# K210 register map
Vendor: Canaan Inc.; File version: 1.0
Registers are 32-bit, read-write, reset 0x0 unless marked. A register's access mark holds for its fields unless they carry their own. Offsets are from the block's base; [hi:lo] are bit positions; {n}, {i} and the like mark numbered series; 'fields as' and 'values as' point back to an identical list.

## KPU — Neural Network Accelerator
Base 0x40800000
0x00 layer_argument_fifo 64-bit (reset mask 0xFFFFFFFF) — Layer arguments FIFO: each layer is defined by writing 12 successive argument values to this register
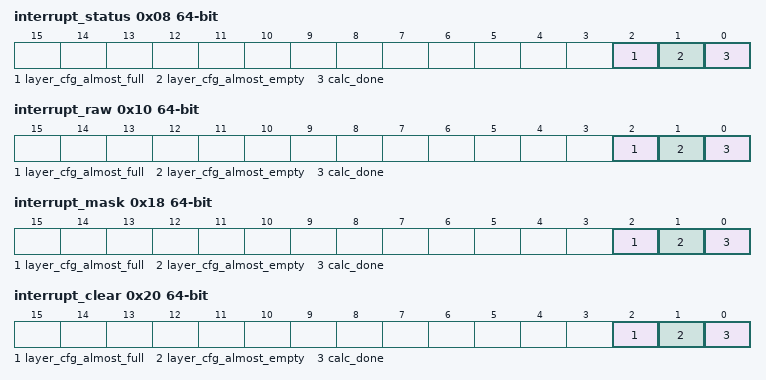
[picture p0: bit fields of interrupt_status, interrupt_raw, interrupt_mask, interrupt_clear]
0x08 interrupt_status 64-bit
  [2] layer_cfg_almost_full — Interrupt raised when layer arguments FIFO almost full
  [1] layer_cfg_almost_empty — Interrupt raised when layer arguments FIFO almost empty
  [0] calc_done — Interrupt raised when calculation is done
0x10 interrupt_raw 64-bit
  fields as interrupt_status
0x18 interrupt_mask 64-bit — Interrupt mask: 0 enables the interrupt, 1 masks the interrupt
  fields as interrupt_status
0x20 interrupt_clear 64-bit — Interrupt clear: write 1 to a bit to clear interrupt
  fields as interrupt_status
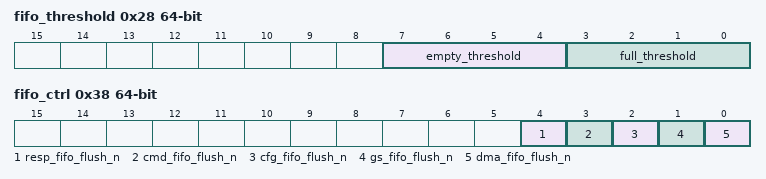
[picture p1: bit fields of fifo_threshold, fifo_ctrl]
0x28 fifo_threshold 64-bit
  [7:4] empty_threshold — FIFO empty threshold
  [3:0] full_threshold — FIFO full threshold
0x30 fifo_data_out 64-bit (reset mask 0xFFFFFFFF) — FIFO data output
0x38 fifo_ctrl 64-bit — FIFO control
  [4] resp_fifo_flush_n — Flush response FIFO
  [3] cmd_fifo_flush_n — Flush command FIFO
  [2] cfg_fifo_flush_n — Flush configuration FIFO
  [1] gs_fifo_flush_n — Flush GS FIFO
  [0] dma_fifo_flush_n — Flush DMA FIFO
0x40 eight_bit_mode 64-bit
  [0] eight_bit_mode — Use 8-bit instead of 16-bit precision if set

## FFT — Fast Fourier Transform Accelerator
Base 0x42000000
0x00 input_fifo 64-bit (reset mask 0xFFFFFFFF) — FFT input data fifo
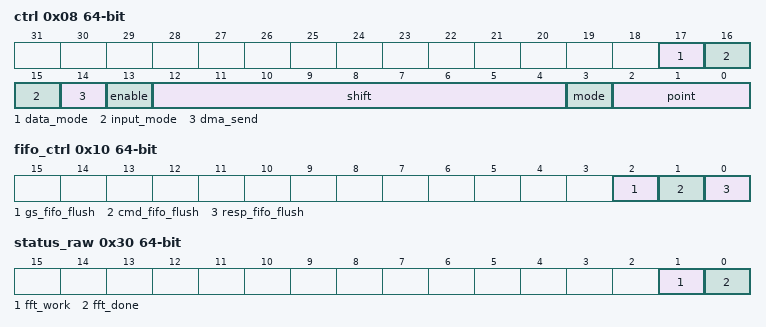
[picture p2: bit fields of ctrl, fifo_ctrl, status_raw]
0x08 ctrl 64-bit — FFT control register
  [17] data_mode — Effective width of input data
    0=width_64 (64 bit effective); 1=width_128 (128 bit effective)
  [16:15] input_mode — Input data arrangement
    0=RIRI (real imaginary interleaved); 1=RRRR (only real part); 2=rrii (First input the real part and then input the imaginary part)
  [14] dma_send — FFT DMA enable
  [13] enable — FFT enable
  [12:4] shift — Corresponding to the nine layer butterfly shift operation, 0x0: does not shift; 0x1: shift 1st layer. ...
  [3] mode — FFT mode
    0=fft (FFT mode); 1=ifft (Inverse FFT mode)
  [2:0] point — FFT calculation data length
    0=p512 (512 point); 1=p256 (256 point); 2=p128 (128 point); 3=p64 (64 point)
0x10 fifo_ctrl 64-bit — FIFO control
  [2] gs_fifo_flush — Output interface memory initialization flag
  [1] cmd_fifo_flush — Command memory initialization flag
  [0] resp_fifo_flush — Response memory initialization flag
0x18 interrupt mask 64-bit — intr_mask
  [0] fft_done
0x20 intr_clear 64-bit — Interrupt clear
  [0] fft_done
0x28 status 64-bit — FFT status register
  [0] fft_done
0x30 status_raw 64-bit — FFT status raw
  [1] fft_work, [0] fft_done
0x38 output_fifo 64-bit (reset mask 0xFFFFFFFF) — FFT output FIFO

## GPIO — General Purpose Input/Output Interface
Base 0x50200000
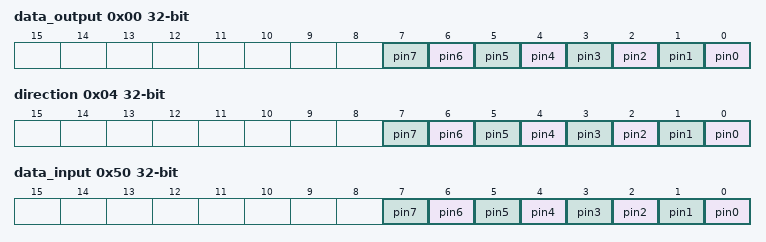
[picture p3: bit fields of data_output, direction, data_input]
0x00 data_output — Data (output) registers
  [n] pin{n} (n=0..7)
0x04 direction — Data direction registers
  [n] pin{n} (n=0..7)
    0=input (Pin is input); 1=output (Pin is output)
0x08 source — Data source registers
0x30 interrupt_enable — Interrupt enable/disable registers
0x34 interrupt_mask — Interrupt mask registers
0x38 interrupt_level — Interrupt level registers
0x3C interrupt_polarity — Interrupt polarity registers
0x40 interrupt_status — Interrupt status registers
0x44 interrupt_status_raw — Raw interrupt status registers
0x48 interrupt_debounce — Interrupt debounce registers
0x4C interrupt_clear — Registers for clearing interrupts
0x50 data_input — External port (data input) registers
  [n] pin{n} (n=0..7)
0x60 sync_level — Sync level registers
0x64 id_code
0x68 interrupt_bothedge — Interrupt both edge type

## UART1 — Universal Asynchronous Receiver-Transmitter 1
Base 0x50210000
Same registers: UART2 0x50220000, UART3 0x50230000
0x00 rbr_dll_thr — Receive Buffer Register / Divisor Latch (Low) / Transmit Holding Register (depending on context and R/W)
0x04 dlh_ier — Divisor Latch (High) / Interrupt Enable Register
0x08 fcr_iir — FIFO Control Register / Interrupt Identification Register
0x0C lcr — Line Control Register
0x10 mcr — Modem Control Register
0x14 lsr — Line Status Register
0x18 msr — Modem Status Register
0x1C scr — Scratchpad Register
0x20 lpdll — Low Power Divisor Latch (Low) Register
0x24 lpdlh — Low Power Divisor Latch (High) Register
{0x30+4i} srbr_sthr[{i}] (i=0..15) — Shadow Receive Buffer Register / Shadow Transmit Holding Register (depending on R/W)
0x70 far — FIFO Access Register
0x74 tfr — Transmit FIFO Read Register
0x78 rfw — Receive FIFO Write Register
0x7C usr — UART Status Register
0x80 tfl — Transmit FIFO Level
0x84 rfl — Receive FIFO Level
0x88 srr — Software Reset Register
0x8C srts — Shadow Request to Send Register
0x90 sbcr — Shadow Break Control Register
0x94 sdmam — Shadow DMA Mode
0x98 sfe — Shadow FIFO Enable
0x9C srt — Shadow RCVR Trigger Register
0xA0 stet — Shadow TX Empty Trigger Register
0xA4 htx — Halt TX Regster
0xA8 dmasa — DMA Software Acknowledge Register
0xAC tcr — Transfer Control Register
0xB0 de_en — DE Enable Register
0xB4 re_en — RE Enable Register
0xB8 det — DE Assertion Time Register
0xBC tat — Turn-Around Time Register
0xC0 dlf — Divisor Latch (Fractional) Register
0xC4 rar — Receive-Mode Address Register
0xC8 tar — Transmit-Mode Address Register
0xCC lcr_ext — Line Control Register (Extended)
0xF4 cpr — Component Parameter Register
0xF8 ucv — UART Component Version
0xFC ctr — Component Type Register
